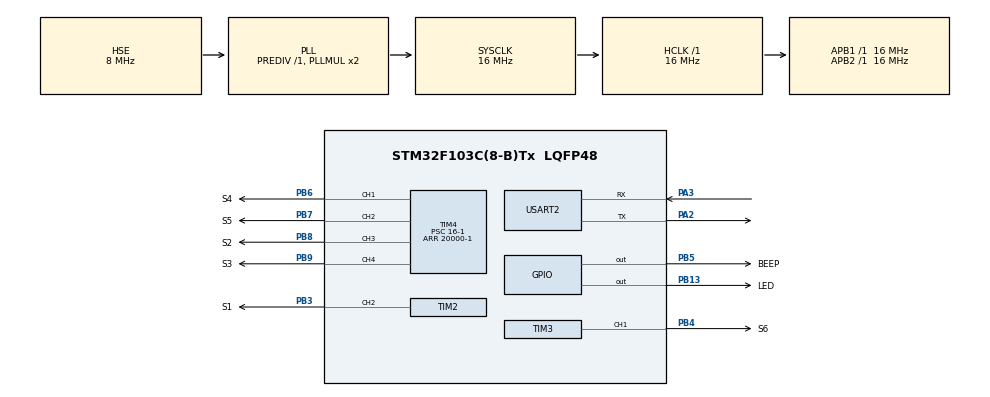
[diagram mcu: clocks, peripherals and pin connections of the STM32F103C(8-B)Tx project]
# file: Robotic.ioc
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FREERTOS.INCLUDE_eTaskGetState=1
FREERTOS.INCLUDE_pcTaskGetTaskName=1
FREERTOS.INCLUDE_uxTaskGetStackHighWaterMark=1
FREERTOS.INCLUDE_vTaskCleanUpResources=1
FREERTOS.INCLUDE_vTaskDelayUntil=1
FREERTOS.INCLUDE_xQueueGetMutexHolder=1
FREERTOS.INCLUDE_xSemaphoreGetMutexHolder=1
FREERTOS.INCLUDE_xTaskAbortDelay=1
FREERTOS.INCLUDE_xTaskGetCurrentTaskHandle=1
FREERTOS.INCLUDE_xTaskGetHandle=1
FREERTOS.Tasks01=defaultTask,-1,128,StartDefaultTask,As weak,NULL,Dynamic,NULL,NULL;controlTask,2,128,ControlTaskFunction,As weak,NULL,Dynamic,NULL,NULL
Mcu.Family=STM32F1
Mcu.Name=STM32F103C(8-B)Tx
Mcu.Package=LQFP48
NVIC.PriorityGroup=NVIC_PRIORITYGROUP_4
NVIC.TIM1_UP_IRQn=true\:15\:0\:false\:false\:true\:false\:false\:true\:true
NVIC.TimeBase=TIM1_UP_IRQn
NVIC.TimeBaseIP=TIM1
PA13.Mode=Serial_Wire
PA13.Signal=SYS_JTMS-SWDIO
PA14.Mode=Serial_Wire
PA14.Signal=SYS_JTCK-SWCLK
PA2.Mode=Asynchronous
PA2.Signal=USART2_TX
PA3.Mode=Asynchronous
PA3.Signal=USART2_RX
PB13.GPIO_Label=LED
PB13.GPIO_PuPd=GPIO_PULLDOWN
PB13.GPIO_Speed=GPIO_SPEED_FREQ_MEDIUM
PB13.Signal=GPIO_Output
PB3.GPIO_Label=S1
PB3.GPIO_Speed=GPIO_SPEED_FREQ_HIGH
PB3.Signal=S_TIM2_CH2
PB4.GPIO_Label=S6
PB4.GPIO_Speed=GPIO_SPEED_FREQ_HIGH
PB4.Signal=S_TIM3_CH1
PB5.GPIO_Label=BEEP
PB5.GPIO_PuPd=GPIO_PULLDOWN
PB5.GPIO_Speed=GPIO_SPEED_FREQ_MEDIUM
PB5.Signal=GPIO_Output
PB6.GPIO_Label=S4
PB6.GPIO_Speed=GPIO_SPEED_FREQ_HIGH
PB6.Signal=S_TIM4_CH1
PB7.GPIO_Label=S5
PB7.GPIO_Speed=GPIO_SPEED_FREQ_HIGH
PB7.Signal=S_TIM4_CH2
PB8.GPIO_Label=S2
PB8.GPIO_Speed=GPIO_SPEED_FREQ_HIGH
PB8.Signal=S_TIM4_CH3
PB9.GPIO_Label=S3
PB9.GPIO_Speed=GPIO_SPEED_FREQ_HIGH
PB9.Signal=S_TIM4_CH4
PD0-OSC_IN.Mode=HSE-External-Oscillator
PD0-OSC_IN.Signal=RCC_OSC_IN
PD1-OSC_OUT.Mode=HSE-External-Oscillator
PD1-OSC_OUT.Signal=RCC_OSC_OUT
ProjectManager.HeapSize=0x200
ProjectManager.StackSize=0x400
ProjectManager.TargetToolchain=MDK-ARM V5.32
RCC.AHBFreq_Value=16000000
RCC.APB1Freq_Value=16000000
RCC.APB1TimFreq_Value=16000000
RCC.APB2Freq_Value=16000000
RCC.APB2TimFreq_Value=16000000
RCC.HCLKFreq_Value=16000000
RCC.PLLSourceVirtual=RCC_PLLSOURCE_HSE
RCC.SYSCLKFreq_VALUE=16000000
RCC.SYSCLKSource=RCC_SYSCLKSOURCE_PLLCLK
RCC.USBFreq_Value=16000000
SH.S_TIM2_CH2.0=TIM2_CH2,PWM Generation2 CH2
SH.S_TIM3_CH1.0=TIM3_CH1,PWM Generation1 CH1
SH.S_TIM4_CH1.0=TIM4_CH1,PWM Generation1 CH1
SH.S_TIM4_CH2.0=TIM4_CH2,PWM Generation2 CH2
SH.S_TIM4_CH3.0=TIM4_CH3,PWM Generation3 CH3
SH.S_TIM4_CH4.0=TIM4_CH4,PWM Generation4 CH4
TIM2.Channel-PWM\ Generation2\ CH2=TIM_CHANNEL_2
TIM2.Period=20000-1
TIM2.Prescaler=16-1
TIM3.Channel-PWM\ Generation1\ CH1=TIM_CHANNEL_1
TIM3.Period=20000-1
TIM3.Prescaler=16-1
TIM4.Channel-PWM\ Generation1\ CH1=TIM_CHANNEL_1
TIM4.Channel-PWM\ Generation2\ CH2=TIM_CHANNEL_2
TIM4.Channel-PWM\ Generation3\ CH3=TIM_CHANNEL_3
TIM4.Channel-PWM\ Generation4\ CH4=TIM_CHANNEL_4
TIM4.Period=20000-1
TIM4.Prescaler=16-1
USART2.VirtualMode=VM_ASYNC
VP_FREERTOS_VS_CMSIS_V1.Mode=CMSIS_V1
VP_SYS_VS_tim1.Mode=TIM1
VP_TIM2_VS_ClockSourceINT.Mode=Internal
VP_TIM3_VS_ClockSourceINT.Mode=Internal
VP_TIM4_VS_ClockSourceINT.Mode=Internal
board=custom

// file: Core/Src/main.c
/* USER CODE BEGIN Header */
/**
  ******************************************************************************
  * @file           : main.c
  * @brief          : Main program body
  ******************************************************************************
  * @attention
  *
  * Copyright (c) 2022 STMicroelectronics.
  * All rights reserved.
  *
  * This software is licensed under terms that can be found in the LICENSE file
  * in the root directory of this software component.
  * If no LICENSE file comes with this software, it is provided AS-IS.
  *
  ******************************************************************************
  */
/* USER CODE END Header */
#include "main.h"
#include "cmsis_os.h"
#include "tim.h"
#include "usart.h"
#include "gpio.h"

/* USER CODE BEGIN Includes */
#include "control.h"

/* USER CODE END Includes */

void SystemClock_Config(void);
void MX_FREERTOS_Init(void);

int main(void)
{

  /* MCU Configuration--------------------------------------------------------*/

  /* Reset of all peripherals, Initializes the Flash interface and the Systick. */
  HAL_Init();

  /* Configure the system clock */
  SystemClock_Config();

  /* Initialize all configured peripherals */
  MX_GPIO_Init();
  MX_USART2_UART_Init();
  MX_TIM3_Init();
  MX_TIM2_Init();
  MX_TIM4_Init();
  /* USER CODE BEGIN 2 */
	__HAL_UART_ENABLE_IT(&huart2, UART_IT_RXNE); 	// receive interrupt
	HAL_UART_Receive_IT(&huart2, &receive_data, 1);
  /* USER CODE END 2 */

  /* Call init function for freertos objects (in freertos.c) */
  MX_FREERTOS_Init();

  /* Start scheduler */
  osKernelStart();

  /* We should never get here as control is now taken by the scheduler */
  /* Infinite loop */
  while (1)
  {

  }
}

void SystemClock_Config(void)
{
  RCC_OscInitTypeDef RCC_OscInitStruct = {0};
  RCC_ClkInitTypeDef RCC_ClkInitStruct = {0};

  /** Initializes the RCC Oscillators according to the specified parameters
  * in the RCC_OscInitTypeDef structure.
  */
  RCC_OscInitStruct.OscillatorType = RCC_OSCILLATORTYPE_HSE;
  RCC_OscInitStruct.HSEState = RCC_HSE_ON;
  RCC_OscInitStruct.HSEPredivValue = RCC_HSE_PREDIV_DIV1;
  RCC_OscInitStruct.HSIState = RCC_HSI_ON;
  RCC_OscInitStruct.PLL.PLLState = RCC_PLL_ON;
  RCC_OscInitStruct.PLL.PLLSource = RCC_PLLSOURCE_HSE;
  RCC_OscInitStruct.PLL.PLLMUL = RCC_PLL_MUL2;
  if (HAL_RCC_OscConfig(&RCC_OscInitStruct) != HAL_OK)
  {
    Error_Handler();
  }

  /** Initializes the CPU, AHB and APB buses clocks
  */
  RCC_ClkInitStruct.ClockType = RCC_CLOCKTYPE_HCLK|RCC_CLOCKTYPE_SYSCLK
                              |RCC_CLOCKTYPE_PCLK1|RCC_CLOCKTYPE_PCLK2;
  RCC_ClkInitStruct.SYSCLKSource = RCC_SYSCLKSOURCE_PLLCLK;
  RCC_ClkInitStruct.AHBCLKDivider = RCC_SYSCLK_DIV1;
  RCC_ClkInitStruct.APB1CLKDivider = RCC_HCLK_DIV1;
  RCC_ClkInitStruct.APB2CLKDivider = RCC_HCLK_DIV1;

  if (HAL_RCC_ClockConfig(&RCC_ClkInitStruct, FLASH_LATENCY_0) != HAL_OK)
  {
    Error_Handler();
  }
}

void HAL_TIM_PeriodElapsedCallback(TIM_HandleTypeDef *htim)
{
  if (htim->Instance == TIM1) {
    HAL_IncTick();
  }
}

void Error_Handler(void)
{
  __disable_irq();
  while (1)
  {
  }
}

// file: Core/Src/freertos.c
/* USER CODE BEGIN Header */
/**
  ******************************************************************************
  * File Name          : freertos.c
  * Description        : Code for freertos applications
  ******************************************************************************
  * @attention
  *
  * Copyright (c) 2022 STMicroelectronics.
  * All rights reserved.
  *
  * This software is licensed under terms that can be found in the LICENSE file
  * in the root directory of this software component.
  * If no LICENSE file comes with this software, it is provided AS-IS.
  *
  ******************************************************************************
  */
/* USER CODE END Header */

#include "FreeRTOS.h"
#include "task.h"
#include "main.h"
#include "cmsis_os.h"

osThreadId defaultTaskHandle;
osThreadId controlTaskHandle;

void StartDefaultTask(void const * argument);
void ControlTaskFunction(void const * argument);

void MX_FREERTOS_Init(void); /* (MISRA C 2004 rule 8.1) */

/* GetIdleTaskMemory prototype (linked to static allocation support) */
void vApplicationGetIdleTaskMemory( StaticTask_t **ppxIdleTaskTCBBuffer, StackType_t **ppxIdleTaskStackBuffer, uint32_t *pulIdleTaskStackSize );

/* USER CODE BEGIN GET_IDLE_TASK_MEMORY */
static StaticTask_t xIdleTaskTCBBuffer;
static StackType_t xIdleStack[configMINIMAL_STACK_SIZE];

void vApplicationGetIdleTaskMemory( StaticTask_t **ppxIdleTaskTCBBuffer, StackType_t **ppxIdleTaskStackBuffer, uint32_t *pulIdleTaskStackSize )
{
  *ppxIdleTaskTCBBuffer = &xIdleTaskTCBBuffer;
  *ppxIdleTaskStackBuffer = &xIdleStack[0];
  *pulIdleTaskStackSize = configMINIMAL_STACK_SIZE;
  /* place for user code */
}
/* USER CODE END GET_IDLE_TASK_MEMORY */

void MX_FREERTOS_Init(void) {

  /* Create the thread(s) */
  /* definition and creation of defaultTask */
  osThreadDef(defaultTask, StartDefaultTask, osPriorityBelowNormal, 0, 128);
  defaultTaskHandle = osThreadCreate(osThread(defaultTask), NULL);

  /* definition and creation of controlTask */
  osThreadDef(controlTask, ControlTaskFunction, osPriorityHigh, 0, 128);
  controlTaskHandle = osThreadCreate(osThread(controlTask), NULL);

}

__weak void StartDefaultTask(void const * argument)
{
  for(;;)
  {
	  osDelay(1);
  }
}

__weak void ControlTaskFunction(void const * argument)
{
  for(;;)
  {
    osDelay(1);
  }
}
